AUTOSAR XML (schema 314)
package /ComponentType
  internal behavior Sa_MtrVel_InternalBehavior: component=Sa_MtrVel
    timing event MtrVel_InitEvent: start-on-event=MtrVel_Init, period=0
    timing event TMT_MtrVel_Per1: start-on-event=MtrVel_Per1, period=0.002
    timing event TMT_MtrVel_Per2: start-on-event=MtrVel_Per2, period=0.002
    port-api-options:
      enable-take-address=false, indirect-api=false, port=AsstAssemblyPolarity
      enable-take-address=false, indirect-api=false, port=HandwheelVel
      enable-take-address=false, indirect-api=false, port=HwVelValid
      enable-take-address=false, indirect-api=false, port=MechMtrPos2
      enable-take-address=false, indirect-api=false, port=MechMtrPos2Timestamp
      enable-take-address=false, indirect-api=false, port=MotorVelCRF
      enable-take-address=false, indirect-api=false, port=MotorVelMRF
      enable-take-address=false, indirect-api=false, port=NxtrDiagMgr
      enable-take-address=false, indirect-api=false, port=SysCDiagHwVel
      enable-take-address=false, indirect-api=false, port=SysCDiagMtrVelMRF
      enable-take-address=false, indirect-api=false, port=SysCHandwheelVel
      enable-take-address=false, indirect-api=false, port=SysCMotorVelMRF
    runnable MtrVel_Init
    runnable MtrVel_Per1
      data read access READ_AsstAssemblyPolarity_Cnt_s08: data-element=AsstAssemblyPolarity.Cnt_s08
      data read access READ_MechMtrPos2_Rev_u0p16: data-element=MechMtrPos2.Rev_u0p16
      data read access READ_MechMtrPos2Timestamp_USec_u32: data-element=MechMtrPos2Timestamp.USec_u32
      5 x data write access:
        WRITE_HandwheelVel_HwRadpS_f32: data-element=HandwheelVel.HwRadpS_f32
        WRITE_MotorVelCRF_MtrRadpS_f32: data-element=MotorVelCRF.MtrRadpS_f32
        WRITE_MotorVelMRF_MtrRadpS_f32: data-element=MotorVelMRF.MtrRadpS_f32
        WRITE_SysCHandwheelVel_HwRadpS_f32: data-element=SysCHandwheelVel.HwRadpS_f32
        WRITE_SysCMotorVelMRF_MtrRadpS_f32: data-element=SysCMotorVelMRF.MtrRadpS_f32
    runnable MtrVel_Per2
      data read access READ_SysCDiagHwVel_HwRadpS_f32: data-element=SysCDiagHwVel.HwRadpS_f32
      data read access READ_SysCDiagMtrVelMRF_MtrRadpS_f32: data-element=SysCDiagMtrVelMRF.MtrRadpS_f32
      data write access WRITE_HwVelValid_Cnt_lgc: data-element=HwVelValid.Cnt_lgc
      sync call SC_NxtrDiagMgr_GetNTCFailed: operation=NxtrDiagMgr.GetNTCFailed, timeout=0
      sync call SC_NxtrDiagMgr_SetNTCStatus: operation=NxtrDiagMgr.SetNTCStatus, timeout=0
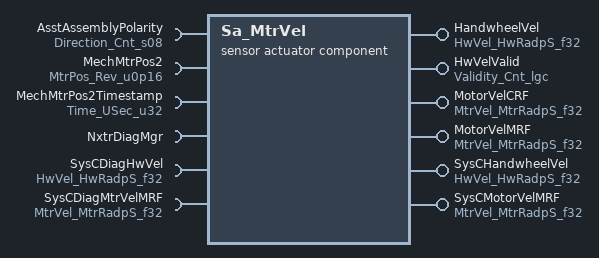
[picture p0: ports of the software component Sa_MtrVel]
  sensor actuator software component type Sa_MtrVel
    6 x provide port:
      HandwheelVel: unqueued-sender-com-spec{data-element=HwRadpS_f32, can-invalidate=false, init-value=D_ZERO_ULS_F32}, provided-interface=HwVel_HwRadpS_f32
      HwVelValid: unqueued-sender-com-spec{data-element=Cnt_lgc, can-invalidate=false, init-value=D_FALSE_CNT_LGC}, provided-interface=Validity_Cnt_lgc
      MotorVelCRF: unqueued-sender-com-spec{data-element=MtrRadpS_f32, can-invalidate=false, init-value=D_ZERO_ULS_F32}, provided-interface=MtrVel_MtrRadpS_f32
      MotorVelMRF: unqueued-sender-com-spec{data-element=MtrRadpS_f32, can-invalidate=false, init-value=D_ZERO_ULS_F32}, provided-interface=MtrVel_MtrRadpS_f32
      SysCHandwheelVel: unqueued-sender-com-spec{data-element=HwRadpS_f32, can-invalidate=false, init-value=D_ZERO_ULS_F32}, provided-interface=HwVel_HwRadpS_f32
      SysCMotorVelMRF: unqueued-sender-com-spec{data-element=MtrRadpS_f32, can-invalidate=false, init-value=D_ZERO_ULS_F32}, provided-interface=MtrVel_MtrRadpS_f32
    6 x require port:
      AsstAssemblyPolarity: unqueued-receiver-com-spec{data-element=Cnt_s08, init-value=D_ZERO_CNT_S8}, required-interface=Direction_Cnt_s08
      MechMtrPos2: unqueued-receiver-com-spec{data-element=Rev_u0p16, init-value=D_ZERO_CNT_U16}, required-interface=MtrPos_Rev_u0p16
      MechMtrPos2Timestamp: unqueued-receiver-com-spec{data-element=USec_u32, init-value=D_ZERO_CNT_U32}, required-interface=Time_USec_u32
      NxtrDiagMgr: required-com-specs=[GetNTCActive, GetNTCFailed, GetNTCStatus, SetNTCStatus], required-interface=NxtrDiagMgr
      SysCDiagHwVel: unqueued-receiver-com-spec{data-element=HwRadpS_f32, init-value=D_ZERO_ULS_F32}, required-interface=HwVel_HwRadpS_f32
      SysCDiagMtrVelMRF: unqueued-receiver-com-spec{data-element=MtrRadpS_f32, init-value=D_ZERO_ULS_F32}, required-interface=MtrVel_MtrRadpS_f32
  swc implementation Sa_MtrVel_Implementation: behavior=Sa_MtrVel_InternalBehavior
    code-descriptors:
      code Code: type=SRC
